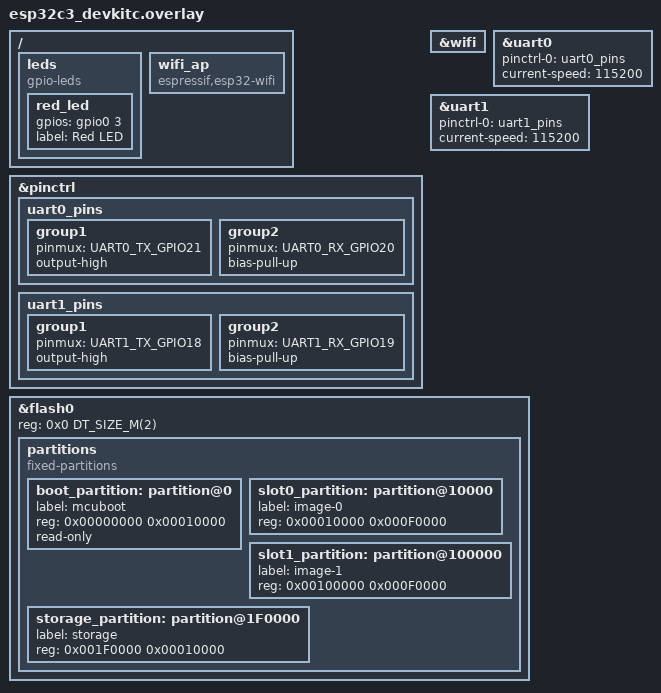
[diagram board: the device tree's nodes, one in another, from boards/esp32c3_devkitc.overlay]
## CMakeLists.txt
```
# SPDX-License-Identifier: Apache-2.0 OR MIT

cmake_minimum_required(VERSION 3.20.0)

find_package(Zephyr REQUIRED HINTS $ENV{ZEPHYR_BASE})
project(Project)

file(READ "${CMAKE_SOURCE_DIR}/VERSION" VERSION_RAW)
string(REPLACE "\r\n" "\n" VERSION_RAW "${VERSION_RAW}")
string(REPLACE "\r"   "\n" VERSION_RAW "${VERSION_RAW}")
string(REGEX REPLACE "\n$" "" VERSION_RAW "${VERSION_RAW}")
string(REPLACE "\n" ";" VERSION_LINES "${VERSION_RAW}")
foreach(line IN LISTS VERSION_LINES)
    string(STRIP "${line}" line)
    if(line MATCHES "^([A-Z_]+)[ ]*=[ ]*(.+)$")
        set(KEY "${CMAKE_MATCH_1}")
        set(VAL "${CMAKE_MATCH_2}")
        message(STATUS "Defining ${KEY}=\"${VAL}\"")
        add_compile_definitions(${KEY}="${VAL}")
    endif()
endforeach()

file(GLOB SRC_C_FILES CONFIGURE_DEPENDS "src/*.c")
target_sources(app PRIVATE ${SRC_C_FILES})

rust_cargo_application()
```

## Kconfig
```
# Copyright (c) 2025
# SPDX-License-Identifier: Apache-2.0
# Coskun ERGAN <coskunergan@gmail.com>

mainmenu "ESP32 Wifi NAT Router Demo"

if WIFI
config NET_IPV4_FORWARDING
    bool "IPv4 forwarding"
    default y
    help
      Enable IPv4 forwarding for AP-STA mode.

config NET_CONFIG_MY_IPV4_ADDR
	string "CONFIG_NET_CONFIG_MY_IPV4_ADDR - Network IP"
	default "192.168.1.77"		  

config NET_CONFIG_MY_IPV4_NETMASK
	string "CONFIG_NET_CONFIG_MY_IPV4_NETMASK - Network Mask"
	default "255.255.255.0"	

config NET_CONFIG_MY_IPV4_GW
	string "CONFIG_NET_CONFIG_MY_IPV4_GW - Network GW"
	default "192.168.1.1"	

config WIFI_SAMPLE_AP_IP_ADDRESS
	string "CONFIG_WIFI_SAMPLE_AP_IP_ADDRESS - Network IP"
	default "192.168.4.1"	

config WIFI_SAMPLE_AP_NETMASK
	string "CONFIG_WIFI_SAMPLE_AP_NETMASK - Network NETMASK"
	default "255.255.255.0"	

config WIFI_SAMPLE_SSID
	string "WIFI SSID - Network name"
	default "router_ssid"

config WIFI_SAMPLE_PSK
	string "WIFI PSK - Network password key"
	default "router_pass"

config WIFI_SAMPLE_AP_SSID
	string "WIFI AP SSID - Network name"
	default "NAT_ROUTER_AP"

config WIFI_SAMPLE_AP_PSK
	string "WIFI AP PSK - Network password key"
	default "deneme123"	

endif # WIFI

menuconfig NET_IPV4_NAT
	bool "Network Address Translation (NAT) support"
	depends on NET_IPV4
	help
	  Enable NAT support for IPv4. This allows the device to act as
	  a router with network address translation capabilities.

if NET_IPV4_NAT

config NET_IPV4_NAT_MAX_ENTRIES
	int "Maximum number of NAT entries"
	default 128
	help
	  Maximum number of simultaneous NAT connections.

config NET_IPV4_NAT_TIMEOUT
	int "NAT entry timeout (seconds)"
	default 300
	help
	  Timeout for inactive NAT entries in seconds.

endif # NET_IPV4_NAT

source "Kconfig.zephyr"
```

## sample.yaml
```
# See doc/develop/test/twister.rst for what is here.
sample:
  name: Rust NAT Router Sample
common:
  filter: CONFIG_RUST_SUPPORTED
  platform_allow:
    - qemu_riscv32
    - qemu_riscv64    
    - esp32c3_devkitc
    - esp32c6_devkitc
tests:
  sample.basic.drivers:
    tags:
    filter: 
    depends_on:
    extra_configs:
    harness:
    integration_platforms:
      - esp32c3_devkitc
      - esp32c6_devkitc
```

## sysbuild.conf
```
# Sysbuild configuration file.

# Enable MCUboot using overwrite only mode for this sample.
SB_CONFIG_BOOTLOADER_MCUBOOT=y
SB_CONFIG_MCUBOOT_MODE_OVERWRITE_ONLY=y
```

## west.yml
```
manifest:
  defaults:
    remote: upstream
  remotes:    
    - name: upstream
      url-base: https://github.com/zephyrproject-rtos
    - name: zephyr-lang-rust
      url-base: https://github.com/coskunergan
  projects:
    - name: zephyr
      clone-depth: 1
      revision: tags/v4.3.0
      import:
        name-whitelist:
          - hal_espressif
          - mcuboot
          - mbedtls
    - name: zephyr-lang-rust
      remote: zephyr-lang-rust
      revision: main
      path: modules/lang/rust
    - name: mbedtls
      revision: c5b06d89c9c498d8fc8659ce31f7e53137b6270f
      path: modules/crypto/mbedtls
      groups:
        - crypto      
    - name: mcuboot
      revision: 96576b341ee19f1c3af6622256b0d4f3d408e1e3
      path: bootloader/mcuboot
      groups:
        - bootloader    
    - name: hal_espressif
      revision: af6cfa2e3e7098b596062ab516b80a48a7ba7332
      path: modules/hal/espressif
      west-commands: west/west-commands.yml
      groups:
        - hal
```

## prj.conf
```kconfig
CONFIG_GPIO=y

CONFIG_RUST=y
CONFIG_RUST_ALLOC=y

CONFIG_DEBUG=y
CONFIG_MAIN_STACK_SIZE=8192

CONFIG_SYS_CLOCK_TICKS_PER_SEC=10000

CONFIG_GPIO_ENABLE_DISABLE_INTERRUPT=y

#CONFIG_USERSPACE=y

CONFIG_UART_INTERRUPT_DRIVEN=y
CONFIG_UART_LINE_CTRL=n

CONFIG_CONSOLE=y

CONFIG_BUILD_OUTPUT_HEX=y

CONFIG_POSIX_API=y
CONFIG_WIFI=y

CONFIG_NET_CONFIG_NEED_IPV4=y
CONFIG_NET_CONFIG_NEED_IPV6=y
CONFIG_NET_DHCPV4=y
CONFIG_NET_DHCPV4_SERVER=y

CONFIG_IDLE_STACK_SIZE=1024
CONFIG_ISR_STACK_SIZE=2048
CONFIG_SYSTEM_WORKQUEUE_STACK_SIZE=2304

CONFIG_NET_PKT_RX_COUNT=24
CONFIG_NET_PKT_TX_COUNT=24
CONFIG_NET_BUF_RX_COUNT=32
CONFIG_NET_BUF_TX_COUNT=32
CONFIG_NET_TX_STACK_SIZE=2048
CONFIG_NET_RX_STACK_SIZE=2048
CONFIG_NET_TC_TX_COUNT=1
CONFIG_NET_TC_RX_COUNT=1

CONFIG_NET_CONTEXT_NET_PKT_POOL=y
CONFIG_NET_TCP_TIME_WAIT_DELAY=0
CONFIG_NET_BUF_POOL_USAGE=y

CONFIG_ENTROPY_GENERATOR=y
CONFIG_TEST_RANDOM_GENERATOR=y

CONFIG_WIFI_ESP32=y
CONFIG_ESP32_WIFI_STA_AUTO_DHCPV4=n
CONFIG_ESP32_WIFI_AP_STA_MODE=y

CONFIG_NET_MGMT=y
CONFIG_NET_MGMT_EVENT=y
CONFIG_NET_MGMT_EVENT_INFO=y

CONFIG_WIFI_NM=y
CONFIG_WIFI_NM_MAX_MANAGED_INTERFACES=2
CONFIG_WIFI_NM_WPA_SUPPLICANT_WEP=y
CONFIG_WIFI_NM_WPA_SUPPLICANT_ADVANCED_FEATURES=y
CONFIG_WIFI_NM_WPA_SUPPLICANT_CLI=y
CONFIG_WPA_CLI=y

CONFIG_NET_TCP_WORKQ_STACK_SIZE=4096

CONFIG_NET_CONFIG_AUTO_INIT=n
CONFIG_NET_CONNECTION_MANAGER=y
CONFIG_NET_IF_MAX_IPV4_COUNT=2
CONFIG_NET_IF_MAX_IPV6_COUNT=2
CONFIG_NET_IPV4=y
CONFIG_NET_IPV6=n

CONFIG_NET_L2_WIFI_MGMT=y
CONFIG_NET_MGMT=y   
CONFIG_NET_MGMT_EVENT=y
CONFIG_NET_MGMT_EVENT_INFO=y
CONFIG_NET_MGMT_EVENT_QUEUE_SIZE=32
CONFIG_NET_MGMT_EVENT_STACK_SIZE=4096
CONFIG_NET_SOCKETS_SERVICE_STACK_SIZE=4096
CONFIG_NET_TCP=y
CONFIG_NET_UDP=y
CONFIG_NETWORKING=y

CONFIG_NET_SOCKETS_POLL_MAX=32
CONFIG_ZVFS_OPEN_MAX=36
CONFIG_NET_MAX_CONN=32
CONFIG_NET_MAX_CONTEXTS=32
CONFIG_NET_BUF_FIXED_DATA_SIZE=y
CONFIG_NET_BUF_DATA_SIZE=512

CONFIG_PM=n

CONFIG_NET_TCP_KEEPALIVE=y
CONFIG_NET_TCP_KEEPIDLE_DEFAULT=15
CONFIG_NET_TCP_KEEPINTVL_DEFAULT=10

CONFIG_REQUIRES_FULL_LIBC=y
CONFIG_MBEDTLS=y
CONFIG_MBEDTLS_ENABLE_HEAP=y
CONFIG_MBEDTLS_MD_C=y
CONFIG_NET_CONTEXT_RCVTIMEO=y
CONFIG_NET_CONTEXT_SNDTIMEO=y
CONFIG_NET_TCP_MAX_RECV_WINDOW_SIZE=16384

CONFIG_NET_TCP_RETRY_COUNT=3
CONFIG_NET_TCP_INIT_RETRANSMISSION_TIMEOUT=120

CONFIG_BOOTLOADER_MCUBOOT=y
CONFIG_MCUBOOT_SIGNATURE_KEY_FILE="root-rsa-2048.pem"

CONFIG_ZCBOR=y
CONFIG_CRC=y
CONFIG_MCUMGR=y
CONFIG_STREAM_FLASH=y
CONFIG_FLASH_MAP=y

CONFIG_IMG_MANAGER=y
CONFIG_MCUBOOT_IMG_MANAGER=y
CONFIG_FLASH=y
CONFIG_MCUMGR_GRP_IMG=y
CONFIG_MCUMGR_GRP_STAT=y
CONFIG_MCUBOOT_UTIL_LOG_LEVEL_WRN=y
CONFIG_MCUBOOT_BOOTLOADER_MODE_SINGLE_APP=n

CONFIG_MCUMGR_TRANSPORT_UDP=y
CONFIG_MCUMGR_TRANSPORT_UDP_PORT=1337
CONFIG_MCUMGR_TRANSPORT_UDP_MTU=1024

CONFIG_THREAD_MONITOR=y
CONFIG_MCUMGR_GRP_OS=y
CONFIG_MCUMGR_GRP_OS_TASKSTAT=y
CONFIG_MCUMGR_GRP_SHELL=y
CONFIG_SHELL_BACKEND_SERIAL=y

# CONFIG_SIZE_OPTIMIZATIONS=y
# CONFIG_SIZE_OPTIMIZATIONS_AGGRESSIVE=y

#----------------------

CONFIG_NET_IPV4_NAT=y
CONFIG_NET_IPV4_NAT_TIMEOUT=300
CONFIG_NET_IPV4_NAT_MAX_ENTRIES=128

CONFIG_NET_BUF=y
CONFIG_NET_ROUTING=y
CONFIG_NET_CONFIG_SETTINGS=n
# CONFIG_NET_STATISTICS=y
CONFIG_NET_IPV4_FORWARDING=y

CONFIG_SHELL=y
CONFIG_SHELL_CMDS=y
CONFIG_NET_SHELL=y
CONFIG_KERNEL_SHELL=y

CONFIG_LOG=y
CONFIG_LOG_DEFAULT_LEVEL=2

# CONFIG_NET_LOG=y
# #CONFIG_LOG_MAX_LEVEL=3
# CONFIG_LOG_BUFFER_SIZE=8192
# CONFIG_LOG_MODE_DEFERRED=y

# CONFIG_NET_L2_ETHERNET_LOG_LEVEL_DBG=y
# CONFIG_NET_DHCPV4_SERVER_LOG_LEVEL_DBG=y
# CONFIG_NET_SOCKETS_LOG_LEVEL_DBG=y
# CONFIG_NET_IF_LOG_LEVEL_DBG=y
# CONFIG_NET_CONN_LOG_LEVEL_DBG=y
# CONFIG_NET_IPV4_LOG_LEVEL_DBG=y
# CONFIG_NET_CORE_LOG_LEVEL_DBG=y
# CONFIG_NET_CONTEXT_LOG_LEVEL_DBG=y
# CONFIG_NET_MGMT_EVENT_LOG_LEVEL_DBG=y
# CONFIG_NET_MGMT_EVENT_LOG_LEVEL_INF=y
# CONFIG_NET_TCP_LOG_LEVEL_DBG=y
# CONFIG_NET_DEBUG_NET_PKT_ALLOC=y
CONFIG_SYS_HEAP_RUNTIME_STATS=y
CONFIG_NET_STATISTICS=y

CONFIG_NET_IPV4_FRAGMENT=n
CONFIG_NET_IF_UNICAST_IPV4_ADDR_COUNT=2

CONFIG_DNS_RESOLVER=y
CONFIG_DNS_SERVER_IP_ADDRESSES=y
CONFIG_DNS_SERVER1="8.8.8.8"
```

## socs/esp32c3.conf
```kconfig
CONFIG_HEAP_MEM_POOL_SIZE=64000
```

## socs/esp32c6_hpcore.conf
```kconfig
CONFIG_HEAP_MEM_POOL_SIZE=100000
```

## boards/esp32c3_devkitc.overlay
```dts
#include <zephyr/dt-bindings/pinctrl/esp-pinctrl-common.h>
#include <dt-bindings/pinctrl/esp32c3-pinctrl.h>
#include <zephyr/dt-bindings/pinctrl/esp32c3-gpio-sigmap.h>

/ { 		
	leds {
		compatible = "gpio-leds";
		red_led: red_led {
			gpios = <&gpio0 3 GPIO_ACTIVE_HIGH>;
			label = "Red LED";
		};
	};
	wifi_ap: wifi_ap {
		compatible = "espressif,esp32-wifi";
		status = "okay";
	};		
};

&pinctrl {
    uart0_pins: uart0_pins {
		group1 {
			pinmux = <UART0_TX_GPIO21>;
			output-high;
		};
		group2 {
			pinmux = <UART0_RX_GPIO20>;
			bias-pull-up;
		};
	};
	uart1_pins: uart1_pins {
		group1 {
			pinmux = <UART1_TX_GPIO18>;
			output-high;
		};
		group2 {
			pinmux = <UART1_RX_GPIO19>;
			bias-pull-up;
		};
	};
};

&wifi {
    status = "okay";
};

&uart0 {
	pinctrl-0 = <&uart0_pins>;
	pinctrl-names = "default";
	current-speed = <115200>;
	status = "okay";	
};

&uart1 {
	pinctrl-0 = <&uart1_pins>;
	pinctrl-names = "default";
	current-speed = <115200>;
	status = "okay";	
};


&flash0 {
    reg = <0x0 DT_SIZE_M(2)>;
    /delete-node/ partitions;
    partitions {
        compatible = "fixed-partitions";
        #address-cells = <1>;
        #size-cells = <1>;

        /* Bootloader - 64KB */
        boot_partition: partition@0 {
            label = "mcuboot";
            reg = <0x00000000 0x00010000>;
            read-only;
        };
        
        /* Slot 0 - 960KB */
        slot0_partition: partition@10000 {
            label = "image-0";
            reg = <0x00010000 0x000F0000>;
        };
        
        /* Slot 1 - 960KB  */
        slot1_partition: partition@100000 {
            label = "image-1";
            reg = <0x00100000 0x000F0000>;
        };
        
        /* Storage - 64KB */
        storage_partition: partition@1F0000 {
            label = "storage";
            reg = <0x001F0000 0x00010000>;
        };
    };
};
```

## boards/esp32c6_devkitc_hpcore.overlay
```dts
#include <zephyr/dt-bindings/pinctrl/esp-pinctrl-common.h>
#include <dt-bindings/pinctrl/esp32c6-pinctrl.h>
#include <zephyr/dt-bindings/pinctrl/esp32c6-gpio-sigmap.h>

/ { 	
	leds {
		compatible = "gpio-leds";
		red_led: red_led {
			gpios = <&gpio0 7 GPIO_ACTIVE_HIGH>;
			label = "Red LED";
		};
	};	
	wifi_ap: wifi_ap {
		compatible = "espressif,esp32-wifi";
		status = "okay";
	};	
};

&wifi {
    status = "okay";
};
```

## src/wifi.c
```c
// Copyright (c) 2025
// SPDX-License-Identifier: Apache-2.0
// Coskun ERGAN <coskunergan@gmail.com>

#include <zephyr/kernel.h>
#include <zephyr/logging/log.h>
#include <zephyr/net/wifi_mgmt.h>
#include <zephyr/net/dhcpv4_server.h>
#include <zephyr/net/dhcpv4.h>
#include <zephyr/net/net_if.h>
#include <zephyr/net/icmp.h>
#include <zephyr/net/socket.h>
#include <zephyr/net/net_core.h>
#include <string.h>
#include <errno.h>

LOG_MODULE_DECLARE(esp32_wifi, LOG_LEVEL_DBG);

#define MACSTR "%02X:%02X:%02X:%02X:%02X:%02X"

#define NET_EVENT_WIFI_MASK                                                                    \
	(NET_EVENT_WIFI_CONNECT_RESULT | NET_EVENT_WIFI_DISCONNECT_RESULT |                        \
	 NET_EVENT_WIFI_AP_ENABLE_RESULT | NET_EVENT_WIFI_AP_DISABLE_RESULT |                      \
	 NET_EVENT_WIFI_AP_STA_CONNECTED | NET_EVENT_WIFI_AP_STA_DISCONNECTED)

static struct wifi_connect_req_params ap_config;
static struct wifi_connect_req_params sta_config;

static struct net_mgmt_event_callback cb;
struct net_if *ap_iface = NULL;
struct net_if *sta_iface = NULL;
static bool connected;

static struct k_work_delayable ip_config_work;

extern uint8_t get_current_ssid_len(void);
extern const uint8_t *get_current_ssid(void);
extern uint8_t get_current_psk_len(void);
extern const uint8_t *get_current_psk(void);
extern int nat_configure(const uint8_t *, const uint8_t *, const uint8_t *, struct net_if *, struct net_if *);

#if CONFIG_NET_DHCPV4_SERVER
static void enable_dhcpv4_server(void)
{
    if(!ap_iface)
    {
        LOG_ERR("AP interface is NULL!");
        return;
    }

    if(!net_if_is_up(ap_iface))
    {
        net_if_up(ap_iface);
        k_sleep(K_MSEC(300));
    }

    struct in_addr ap_ip;
    struct in_addr netmask;
    struct in_addr gateway;

    if(net_addr_pton(AF_INET, CONFIG_WIFI_SAMPLE_AP_IP_ADDRESS, &ap_ip))
    {
        LOG_ERR("Error: Invalid IP address");
        return;
    }

    if(net_addr_pton(AF_INET, CONFIG_WIFI_SAMPLE_AP_NETMASK, &netmask))
    {
        LOG_ERR("Error: Invalid Netmask");
        return;
    }

    gateway = ap_ip;

    net_if_ipv4_addr_rm(ap_iface, &ap_ip);
    net_if_ipv4_addr_add(ap_iface, &ap_ip, NET_ADDR_MANUAL, 0);

    if(!net_if_ipv4_set_netmask_by_addr(ap_iface, &ap_ip, &netmask))
    {
        LOG_ERR("AP Netmask settings failure.");
        return;
    }

    net_if_ipv4_set_gw(ap_iface, &gateway);

    LOG_INF("AP configured → 192.168.4.1/24 | Gateway: 192.168.4.1");

    struct in_addr pool_start = ap_ip;
    pool_start.s4_addr[3] = 100;

    if(net_dhcpv4_server_start(ap_iface, &pool_start) != 0)
    {
        LOG_ERR("DHCP server start failed");
        return;
    }

    LOG_INF("DHCP server STARTED → 192.168.4.100+");
}
#endif

static void ip_config_work_handler(struct k_work *work)
{
    if(!sta_iface)
    {
        LOG_ERR("STA interface is NULL!");
        return;
    }

    net_dhcpv4_stop(sta_iface);

    struct in_addr sta_ip;
    struct in_addr netmask;
    struct in_addr gateway;

    if(net_addr_pton(AF_INET, CONFIG_NET_CONFIG_MY_IPV4_ADDR, &sta_ip))
    {
        LOG_ERR("Error: Invalid IP address");
        return ;
    }
    if(net_addr_pton(AF_INET, CONFIG_NET_CONFIG_MY_IPV4_NETMASK, &netmask))
    {
        LOG_ERR("Error: Invalid Net Mask");
        return;
    }
    if(net_addr_pton(AF_INET, CONFIG_NET_CONFIG_MY_IPV4_GW, &gateway))
    {
        LOG_ERR("Error: Invalid Gateway");
        return;
    }

    net_if_ipv4_addr_rm(sta_iface, &sta_ip);

    if(net_if_ipv4_addr_add(sta_iface, &sta_ip, NET_ADDR_MANUAL, 0) == NULL)
    {
        LOG_ERR("[STA-IP] ERROR: Static IP assaiment failure. Interface state: %s (errno: %d)\n",
                net_if_is_up(sta_iface) ? "UP" : "DOWN", errno);
        return;
    }

    if(!net_if_ipv4_set_netmask_by_addr(sta_iface, &sta_ip, &netmask))
    {
        LOG_ERR("STA Netmask settings failure.");
        return;
    }

    net_if_ipv4_set_gw(sta_iface, &gateway);

    LOG_INF("[STA-IP]   IP:      %u.%u.%u.%u\n",
            sta_ip.s4_addr[0], sta_ip.s4_addr[1],
            sta_ip.s4_addr[2], sta_ip.s4_addr[3]);
    LOG_INF("[STA-IP]   Gateway: %u.%u.%u.%u\n",
            gateway.s4_addr[0], gateway.s4_addr[1],
            gateway.s4_addr[2], gateway.s4_addr[3]);

}

static void wifi_event_handler(struct net_mgmt_event_callback *cb, uint64_t mgmt_event, struct net_if *iface)
{
    switch(mgmt_event)
    {
        case NET_EVENT_WIFI_CONNECT_RESULT:
        {
            const struct wifi_status *status = (const struct wifi_status *)cb->info;

            if(status->status != 0)
            {
                LOG_ERR("Wifi Connection ERROR: %d\n", status->status);
                connected = false;
                break;
            }
            sta_iface = iface;
            connected = true;
            net_if_up(iface);
            net_dhcpv4_stop(iface);
            k_work_init_delayable(&ip_config_work, ip_config_work_handler);
            k_work_schedule(&ip_config_work, K_MSEC(3000));
            break;
        }

        case NET_EVENT_WIFI_DISCONNECT_RESULT:
        {
            connected = false;

            k_work_cancel_delayable(&ip_config_work);
            net_dhcpv4_stop(iface);
            LOG_INF("Disconnected from %s", get_current_ssid());
            break;
        }
        case NET_EVENT_WIFI_AP_STA_CONNECTED:
        {
            struct wifi_ap_sta_info *sta_info = (struct wifi_ap_sta_info *)cb->info;

            LOG_INF("station: " MACSTR " joined ", sta_info->mac[0], sta_info->mac[1],
                    sta_info->mac[2], sta_info->mac[3], sta_info->mac[4], sta_info->mac[5]);

            break;
        }
        case NET_EVENT_WIFI_AP_STA_DISCONNECTED:
        {
            struct wifi_ap_sta_info *sta_info = (struct wifi_ap_sta_info *)cb->info;

            LOG_INF("station: " MACSTR " leave ", sta_info->mac[0], sta_info->mac[1],
                    sta_info->mac[2], sta_info->mac[3], sta_info->mac[4], sta_info->mac[5]);
            break;
        }
        default:
            break;
    }
}

static int enable_ap_mode(void)
{
    LOG_INF("Turning on AP Mode");
    ap_config.ssid = (const uint8_t *)CONFIG_WIFI_SAMPLE_AP_SSID;
    ap_config.ssid_length = sizeof(CONFIG_WIFI_SAMPLE_AP_SSID) - 1;
    ap_config.psk = (const uint8_t *)CONFIG_WIFI_SAMPLE_AP_PSK;

    if(sizeof(CONFIG_WIFI_SAMPLE_AP_PSK) <= 1)
    {
        ap_config.security = WIFI_SECURITY_TYPE_NONE;
        ap_config.psk_length = 0;
    }
    else
    {
        ap_config.security = WIFI_SECURITY_TYPE_PSK;
        ap_config.psk_length = sizeof(CONFIG_WIFI_SAMPLE_AP_PSK) - 1;
    }

    ap_config.channel = WIFI_CHANNEL_ANY;
    ap_config.band = WIFI_FREQ_BAND_2_4_GHZ;


#if CONFIG_NET_DHCPV4_SERVER
    enable_dhcpv4_server();
#endif

    int ret = net_mgmt(NET_REQUEST_WIFI_AP_ENABLE, ap_iface, &ap_config,
                       sizeof(struct wifi_connect_req_params));
    if(ret)
    {
        LOG_ERR("NET_REQUEST_WIFI_AP_ENABLE failed, err: %d", ret);
    }

    return ret;
}

static int connect_to_wifi(void)
{
    sta_config.ssid = get_current_ssid();
    sta_config.ssid_length = get_current_ssid_len();
    sta_config.psk = get_current_psk();
    sta_config.psk_length = get_current_psk_len();
    sta_config.channel = WIFI_CHANNEL_ANY;
    sta_config.band = WIFI_FREQ_BAND_2_4_GHZ;

    if(sta_config.psk_length > 0)
    {
        sta_config.security = WIFI_SECURITY_TYPE_PSK;
    }
    else
    {
        sta_config.security = WIFI_SECURITY_TYPE_NONE;
    }

    LOG_INF("Connecting to SSID: %s (PSK Len: %d, Security: %s)",
            sta_config.ssid, sta_config.psk_length,
            sta_config.security == WIFI_SECURITY_TYPE_PSK ? "PSK" : "NONE");

    int retries = 3;
    int ret;
    connected = false;
    while(retries--)
    {
        LOG_INF("WiFi connect attempt %d...", 2 - retries);

        ret = net_mgmt(NET_REQUEST_WIFI_CONNECT, sta_iface,
                       &sta_config, sizeof(sta_config));

        if(ret != 0)
        {
            if(ret == -EALREADY)
            {
                LOG_INF("WiFi already connected or connecting");
                connected = true;
                break;
            }
            else
            {
                LOG_ERR("net_mgmt() failed: %d", ret);
                k_sleep(K_MSEC(3000));
                continue;
            }
        }

        int timeout = 30;
        while(timeout-- && !connected)
        {
            k_msleep(500);
        }

        if(connected)
        {
            LOG_INF("WiFi connected!");
            break;
        }

        LOG_WRN("Connection timeout, retrying...");
    }

    if(!connected)
    {
        LOG_ERR("WiFi connection failed!");
        return -EIO;
    }

    return 0;
}

void wifi_connect(void)
{
    k_sleep(K_MSEC(500));

    net_mgmt_init_event_callback(&cb, wifi_event_handler, NET_EVENT_WIFI_MASK);
    net_mgmt_add_event_callback(&cb);

    ap_iface = net_if_get_wifi_sap();
    sta_iface = net_if_get_wifi_sta();

    if(!ap_iface || !sta_iface)
    {
        LOG_ERR("AP and STA interface not found!");
        return;
    }

    LOG_INF("AP Interface: 0x%p, STA Interface: 0x%p",
            (void *)ap_iface, (void *)sta_iface);

    if(enable_ap_mode() != 0)
    {
        LOG_ERR("AP mode activation failed!");
        return;
    }

    if(connect_to_wifi() != 0)
    {
        LOG_ERR("WiFi STA connection failed!");
    }

#if defined(CONFIG_NET_IPV4_NAT)    
    uint8_t internal_net[4] = {192, 168, 4, 0};
    uint8_t internal_mask[4];
    uint8_t external_ip[4];

    if(net_addr_pton(AF_INET, CONFIG_NET_CONFIG_MY_IPV4_NETMASK, &internal_mask))
    {
        LOG_ERR("Error: Invalid Net Mask");
        return;
    }

    if(net_addr_pton(AF_INET, CONFIG_NET_CONFIG_MY_IPV4_ADDR, &external_ip))
    {
        LOG_ERR("Error: Invalid IP address");
        return ;
    }    

    if(nat_configure(internal_net, internal_mask, external_ip,
                     ap_iface, sta_iface) < 0)
    {
        LOG_ERR("Failed to configure NAT with interfaces");
    }
    else
    {
        LOG_INF("NAT configured: AP=%p STA=%p", ap_iface, sta_iface);
    }
#endif
}
```
